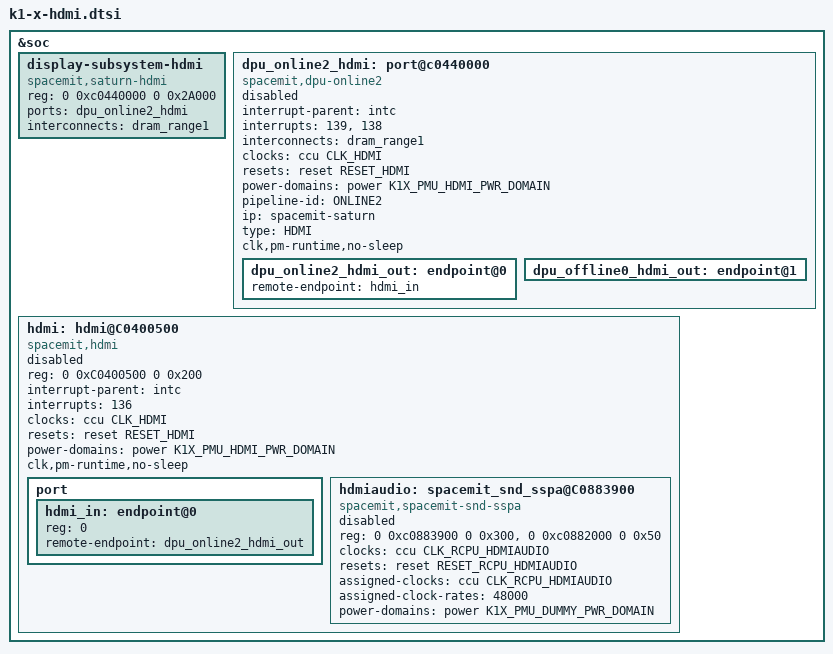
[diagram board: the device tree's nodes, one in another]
// SPDX-License-Identifier: (GPL-2.0 OR MIT)
/* Copyright (c) 2023 Spacemit, Inc */

&soc {
	display-subsystem-hdmi {
		compatible = "spacemit,saturn-hdmi";
		reg = <0 0xc0440000 0 0x2A000>;
		ports = <&dpu_online2_hdmi>;
		interconnects = <&dram_range1>;
		interconnect-names = "dma-mem";
	};

	dpu_online2_hdmi: port@c0440000 {
		compatible = "spacemit,dpu-online2";
		interrupt-parent = <&intc>;
		interrupts = <139>, <138>;
		interrupt-names = "ONLINE_IRQ", "OFFLINE_IRQ";
		interconnects = <&dram_range1>;
		interconnect-names = "dma-mem";
		clocks = <&ccu CLK_HDMI>;
		clock-names = "hmclk";
		resets = <&reset RESET_HDMI>;
		reset-names= "hdmi_reset";
		power-domains = <&power K1X_PMU_HDMI_PWR_DOMAIN>;
		pipeline-id = <ONLINE2>;
		ip = "spacemit-saturn";
		type = <HDMI>;
		clk,pm-runtime,no-sleep;
		status = "disabled";

		dpu_online2_hdmi_out: endpoint@0 {
			remote-endpoint = <&hdmi_in>;
		};

		dpu_offline0_hdmi_out: endpoint@1 {
			/* remote-endpoint = <&wb0_in>; */
		};
	};

	hdmi: hdmi@C0400500 {
		compatible = "spacemit,hdmi", "simple-bus";
		#address-cells = <2>;
		#size-cells = <2>;
		ranges;
		reg = <0 0xC0400500 0 0x200>;
		interrupt-parent = <&intc>;
		interrupts = <136>;
		clocks = <&ccu CLK_HDMI>;
		clock-names = "hmclk";
		resets = <&reset RESET_HDMI>;
		reset-names= "hdmi_reset";
		power-domains = <&power K1X_PMU_HDMI_PWR_DOMAIN>;
		clk,pm-runtime,no-sleep;
		status = "disabled";

		port {
			#address-cells = <1>;
			#size-cells = <0>;
			hdmi_in: endpoint@0 {
				reg = <0>;
				remote-endpoint = <&dpu_online2_hdmi_out>;
			};
		};

		hdmiaudio: spacemit_snd_sspa@C0883900 {
			compatible = "spacemit,spacemit-snd-sspa";
			reg = <0 0xc0883900 0 0x300>,
				<0 0xc0882000 0 0x50>;
			clocks = <&ccu CLK_RCPU_HDMIAUDIO>;
			resets = <&reset RESET_RCPU_HDMIAUDIO>;
			assigned-clocks = <&ccu CLK_RCPU_HDMIAUDIO>;
			assigned-clock-rates = <48000>;
			power-domains = <&power K1X_PMU_DUMMY_PWR_DOMAIN>;
			#sound-dai-cells = <0>;
			status = "disabled";
		};
	};
};
